# MLDR187 register map
File version: 1.4
CPU: MDR32F02, little endian
Registers are 32-bit, read-write, no defined reset value unless marked. A register's access mark holds for its fields unless they carry their own. Offsets are from the block's base; [hi:lo] are bit positions; {n}, {i} and the like mark numbered series; 'fields as' and 'values as' point back to an identical list.

## PBYTE — PBYTE description
Base 0x60028000
{0x0+4i} TRM_{i:02} (i=0..15) — Transformation register {i}
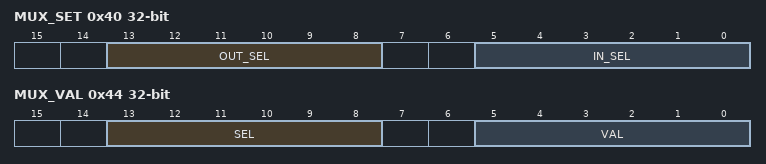
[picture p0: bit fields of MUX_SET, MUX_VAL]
0x40 MUX_SET — Transformation setup register
  [13:8] OUT_SEL wo — OUT_SEL description
  [5:0] IN_SEL wo — IN_SEL description
0x44 MUX_VAL — Transformation value register
  [13:8] SEL wo — SEL description
  [5:0] VAL ro — VAL description

## SBLOCK0 — SBLOCK0 description
Base 0x60008000
Same registers: SBLOCK1 0x6000C000, SBLOCK2 0x60010000, SBLOCK3 0x60014000, SBLOCK4 0x60018000, SBLOCK5 0x6001C000, SBLOCK6 0x60020000, SBLOCK7 0x60024000
{0x0+4i} TRM_{i:02} (i=0..3) — Transformation register {i}
{0x0+4i} TRM_{i:02} (i=4..7) — Transformation register {i-4}
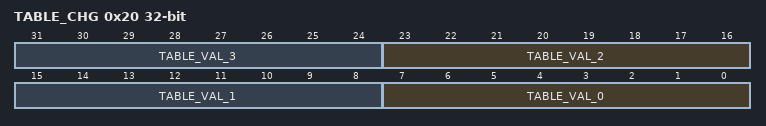
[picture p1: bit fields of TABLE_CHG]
0x20 TABLE_CHG — Table change register
  [8n+7:8n] TABLE_VAL_{n} (n=0..3) — TABLE_VAL_{n} description
0x24 M_SCTRL — Memory special control

## LBLOCK — LBLOCK description
Base 0x60004000
{0x0+4i} TRM_{i:02} (i=0..3) — Transformation register {i}
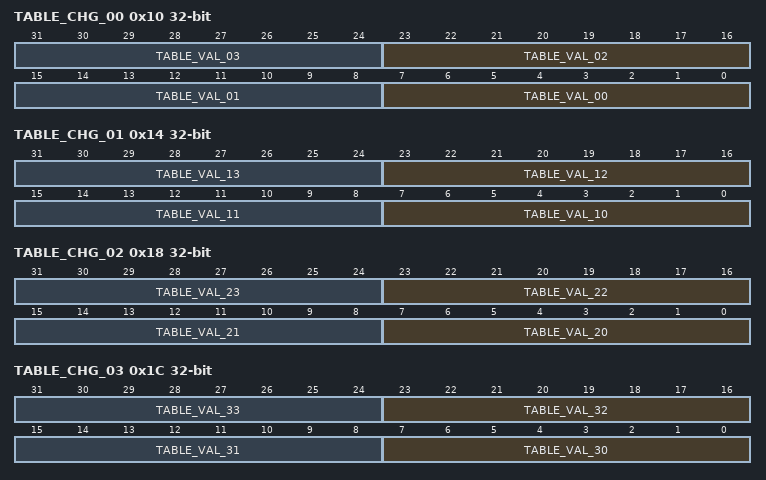
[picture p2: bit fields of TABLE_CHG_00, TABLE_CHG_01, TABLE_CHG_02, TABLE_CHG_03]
0x10 TABLE_CHG_00 — Table change 0 register
  [8n+7:8n] TABLE_VAL_{n:02} (n=0..3) — TABLE_VAL_{n:02} description
0x14 TABLE_CHG_01 — Table change 1 register
  [8n-73:8n-80] TABLE_VAL_{n} (n=10..13) — TABLE_VAL_{n} description
0x18 TABLE_CHG_02 — Table change 2 register
  [8n-153:8n-160] TABLE_VAL_{n} (n=20..23) — TABLE_VAL_{n} description
0x1C TABLE_CHG_03 — Table change 3 register
  [8n-233:8n-240] TABLE_VAL_{n} (n=30..33) — TABLE_VAL_{n} description
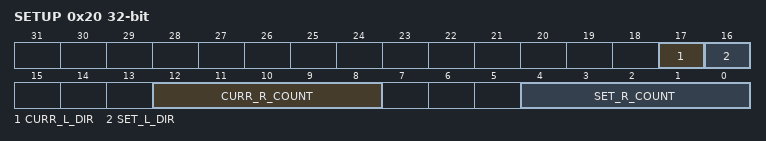
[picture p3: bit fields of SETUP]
0x20 SETUP
  [17] CURR_L_DIR — CURR_L_DIR description
  [16] SET_L_DIR — SET_L_DIR description
  [12:8] CURR_R_COUNT — CURR_R_COUNT description
  [4:0] SET_R_COUNT — SET_R_COUNT description
0x24 M_SCTRL — Memory special control

## P_BIT0 — P_BIT0 description
Base 0x6002C000
Same registers: P_BIT1 0x60030000, P_BIT2 0x60034000, P_BIT3 0x60038000
{0x0+4i} TRANSFORM_{i} (i=0..3) — Transformation register 0
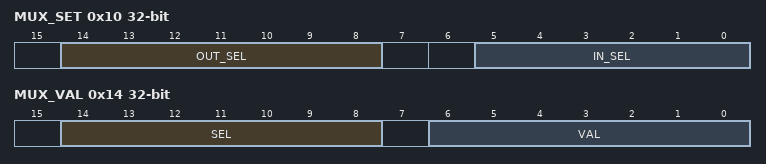
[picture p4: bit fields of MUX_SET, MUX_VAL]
0x10 MUX_SET — Transformation setup register
  [14:8] OUT_SEL wo — Zapis' zadaet perestanovku IN_SEL -> OUT_SEL
  [5:0] IN_SEL wo — Zapis' zadaet perestanovku IN_SEL -> OUT_SEL
0x14 MUX_VAL — Transformation value register
  [14:8] SEL wo — Zapis' v dannoe pole zadaet vyhodnoj bit, dlja kotorogo bude vozvraszeno znachenie perestanovki pri chtenii registra.
  [6:0] VAL ro — Pri chtenii iz dannogo polja vozvraszaetsja znachenie perestanovki dlja vybrannogo cherez SEL vyhodnogo bita.

## RANDOM — RANDOM description
Base 0x400B8000
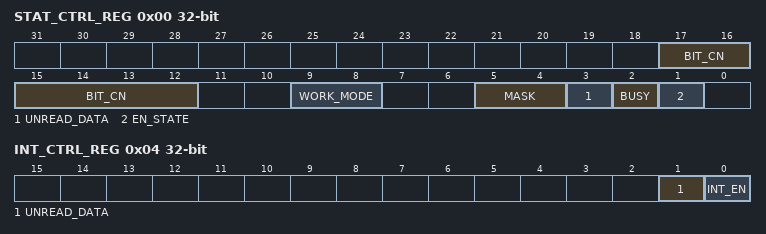
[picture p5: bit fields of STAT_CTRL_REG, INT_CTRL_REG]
0x00 STAT_CTRL_REG — Status and control register
  [17:12] BIT_CN ro — BIT_CN description
  [9:8] WORK_MODE — WORK_MODE description
  [5:4] MASK — MASK description
  [3] UNREAD_DATA ro — UNREAD_DATA description
  [2] BUSY ro — BUSY description
  [1] EN_STATE ro — EN_STATE description
0x04 INT_CTRL_REG — Interrupt control register
  [1] UNREAD_DATA ro — UNREAD_DATA description
  [0] INT_EN — INT_EN description
0x08 CLK_DIV_REG — Clock divider
  [15:0] DIV — DIV description
0x0C PAUSE_REG — Pause register
0x10 OUTPUT_REG ro — Output random
0x14 PAUSE_CNT_REG ro — Pause counter
0x18 TEMP_REG ro — Temp random register

## CLK_MEASURE — CLK_MEASURE description
Base 0x400B0000
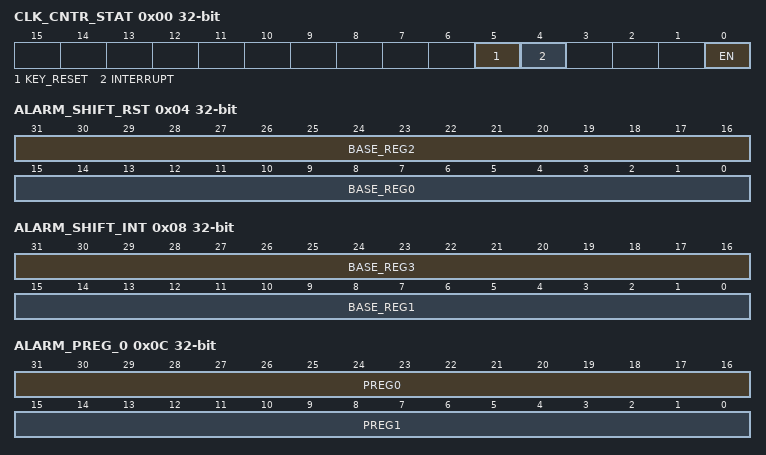
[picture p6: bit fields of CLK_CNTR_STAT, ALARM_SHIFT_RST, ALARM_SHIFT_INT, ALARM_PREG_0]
0x00 CLK_CNTR_STAT — Registr nastroek i sostojanija
  [5] KEY_RESET — KEY_RESET description
  [4] INTERRUPT — INTERRUPT description
  [0] EN — EN description
0x04 ALARM_SHIFT_RST — Registr zadanija porogovyh znachenij dlja signala sbrosa
  [31:16] BASE_REG2 — BASE_REG2 description
  [15:0] BASE_REG0 — BASE_REG0 description
0x08 ALARM_SHIFT_INT — Registr zadanija porogovyh znachenij dlja signala preryvanija
  [31:16] BASE_REG3 — BASE_REG3 description
  [15:0] BASE_REG1 — BASE_REG1 description
0x0C ALARM_PREG_0 — Registr nastrojki parametrov sbrosa schetchikov
  [31:16] PREG0 — PREG0 description
  [15:0] PREG1 — PREG1 description
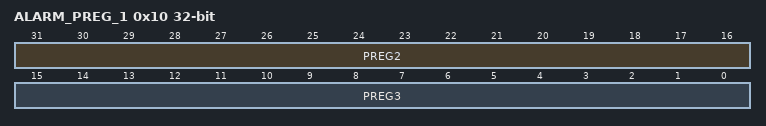
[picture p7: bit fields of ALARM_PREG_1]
0x10 ALARM_PREG_1 — Registr nastrojki parametrov sbrosa schetchikov
  [31:16] PREG2 — PREG2 description
  [15:0] PREG3 — PREG3 description
0x14 CLK_STAT — Registr maksimal'nogo znachenija SHIFT_REG kazhdogo iz kanalov

## SENSORS — SENSORS description
Base 0x400A8000
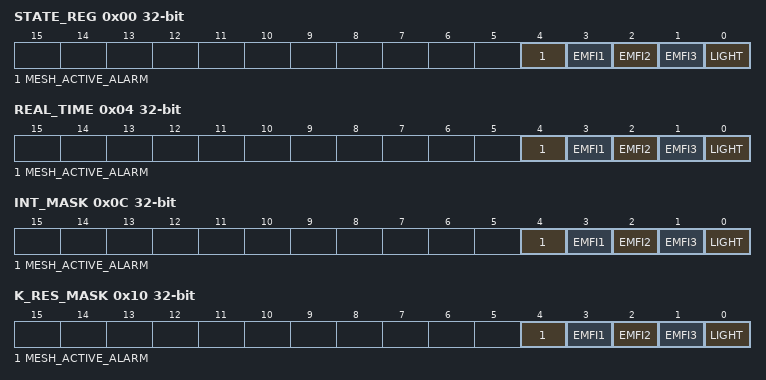
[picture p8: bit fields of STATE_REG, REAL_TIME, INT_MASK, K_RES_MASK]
0x00 STATE_REG — Registr statusa signaly s datchikov
  [4] MESH_ACTIVE_ALARM — MESH_ACTIVE_ALARM description
  [3] EMFI1 — EMFI1 description
  [2] EMFI2 — EMFI2 description
  [1] EMFI3 — EMFI3 description
  [0] LIGHT — LIGHT description
0x04 REAL_TIME — Registr monitoringa sostojanija vhodov sensorov
  [4] MESH_ACTIVE_ALARM ro — MESH_ACTIVE_ALARM description
  [3] EMFI1 ro — EMFI1 description
  [2] EMFI2 ro — EMFI2 description
  [1] EMFI3 ro — EMFI3 description
  [0] LIGHT ro — LIGHT description
0x0C INT_MASK — Registr maski zaprosa preryvanija
  fields as STATE_REG
0x10 K_RES_MASK — Registr maski zaprosa sbrosa
  fields as STATE_REG
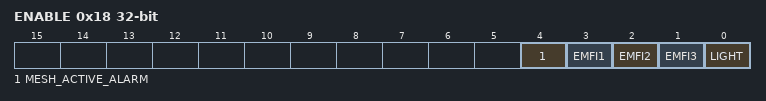
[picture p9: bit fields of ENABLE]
0x18 ENABLE — Registr vkljuchenija datchikov
  fields as STATE_REG
0x1C MESH_KEY7 — Registr kljucha zaszitnoj setki 0 (bity 255:224)
0x20 MESH_KEY6 — Registr kljucha zaszitnoj setki 1 (bity 223:192)
0x24 MESH_KEY5 — Registr kljucha zaszitnoj setki 2 (bity 191:160)
0x28 MESH_KEY4 — Registr kljucha zaszitnoj setki 3 (bity 159:128)
0x2C MESH_KEY3 — Registr kljucha zaszitnoj setki 4 (bity 127:96)
0x30 MESH_KEY2 — Registr kljucha zaszitnoj setki 5 (bity 95:64)
0x34 MESH_KEY1 — Registr kljucha zaszitnoj setki 6 (bity 63:32)
0x38 MESH_KEY0 — Registr kljucha zaszitnoj setki 7 (bity 31:0)
0x3C MESH_INIT1 — Registr inicializacii dannyh zaszitnoj setki 0 (bity 63:32)
0x40 MESH_INIT0 — Registr inicializacii dannyh zaszitnoj setki 1 (bity 31:0)
0x44 MESHCNTR — Registr upravlenija zaszitnoj setki
  [2:0] DIV — DIV description
